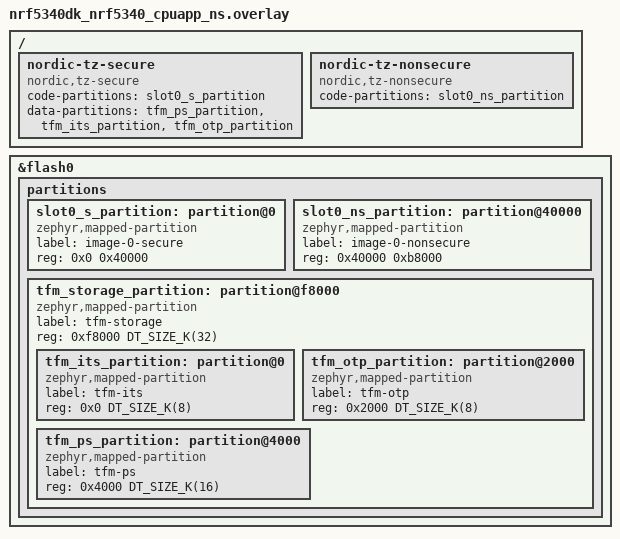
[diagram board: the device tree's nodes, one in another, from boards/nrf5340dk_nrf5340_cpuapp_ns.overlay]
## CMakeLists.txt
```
#
# Copyright (c) 2023 Nordic Semiconductor ASA
#
# SPDX-License-Identifier: LicenseRef-Nordic-5-Clause
#

cmake_minimum_required(VERSION 3.20.0)

if(NOT crypto_service IN_LIST SNIPPET)
  set(SNIPPET crypto_service ${SNIPPET} CACHE STRING "" FORCE)
endif()

find_package(Zephyr REQUIRED HINTS $ENV{ZEPHYR_BASE})

project(pbkdf2)

target_sources(app PRIVATE
        src/main.c)
```

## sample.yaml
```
sample:
  description: |
    This sample demonstrates key derivation using the PBKDF2 algorithm with HMAC-SHA-256.
  name: PBKDF2 sample
common:
  sysbuild: true
  tags:
    - introduction
    - psa
    - sysbuild
    - ci_samples_crypto
    - crypto
  harness: console
  harness_config:
    type: multi_line
    regex:
      - ".*Example finished successfully!.*"
tests:
  sample.pbkdf2.cc3xx:
    tags:
      - cc3xx
    platform_allow:
      - nrf5340dk/nrf5340/cpuapp
      - nrf52840dk/nrf52840
      - nrf5340dk/nrf5340/cpuapp/ns
      - nrf9151dk/nrf9151
      - nrf9151dk/nrf9151/ns
    integration_platforms:
      - nrf5340dk/nrf5340/cpuapp
      - nrf5340dk/nrf5340/cpuapp/ns
      - nrf52840dk/nrf52840
      - nrf9151dk/nrf9151
      - nrf9151dk/nrf9151/ns
  sample.pbkdf2.cracen:
    sysbuild: true
    tags:
      - cracen
    platform_allow:
      - nrf54l15dk/nrf54l15/cpuapp
      - nrf54l15dk/nrf54l15/cpuapp/ns
      - nrf54l15dk/nrf54l10/cpuapp
      - nrf54l15dk/nrf54l10/cpuapp/ns
      - nrf54l15dk/nrf54l05/cpuapp
      - nrf54ls05dk/nrf54ls05a/cpuapp
      - nrf54ls05dk/nrf54ls05b/cpuapp
      - nrf54lm20dk/nrf54lm20a/cpuapp
      - nrf54lm20dk/nrf54lm20a/cpuapp/ns
      - nrf54lm20dk/nrf54lm20b/cpuapp
      - nrf54lm20dk/nrf54lm20b/cpuapp/ns
      - nrf54lv10dk/nrf54lv10a/cpuapp
      - nrf54lv10dk/nrf54lv10a/cpuapp/ns
      - nrf54lc10dk/nrf54lc10a/cpuapp
      - nrf54lc10dk/nrf54lc10a/cpuapp/ns
      - nrf7120dk/nrf7120/cpuapp
      - nrf7120dk/nrf7120/cpuapp/ns
    integration_platforms:
      - nrf54l15dk/nrf54l15/cpuapp
      - nrf54l15dk/nrf54l15/cpuapp/ns
      - nrf54l15dk/nrf54l10/cpuapp
      - nrf54l15dk/nrf54l10/cpuapp/ns
      - nrf54l15dk/nrf54l05/cpuapp
      - nrf54ls05dk/nrf54ls05a/cpuapp
      - nrf54ls05dk/nrf54ls05b/cpuapp
      - nrf54lm20dk/nrf54lm20a/cpuapp
      - nrf54lm20dk/nrf54lm20a/cpuapp/ns
      - nrf54lm20dk/nrf54lm20b/cpuapp
      - nrf54lm20dk/nrf54lm20b/cpuapp/ns
      - nrf54lv10dk/nrf54lv10a/cpuapp
      - nrf54lv10dk/nrf54lv10a/cpuapp/ns
      - nrf54lc10dk/nrf54lc10a/cpuapp
      - nrf54lc10dk/nrf54lc10a/cpuapp/ns
      - nrf7120dk/nrf7120/cpuapp
      - nrf7120dk/nrf7120/cpuapp/ns
  sample.hmac.pbkdf2.crypto_service:
    tags:
      - cracen
    platform_allow:
      - nrf54h20dk/nrf54h20/cpuapp
    integration_platforms:
      - nrf54h20dk/nrf54h20/cpuapp
```

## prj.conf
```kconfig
#
# Copyright (c) 2024 Nordic Semiconductor ASA
#
# SPDX-License-Identifier: LicenseRef-Nordic-5-Clause
#
# The Zephyr CMSIS emulation assumes that ticks are ms, currently
CONFIG_SYS_CLOCK_TICKS_PER_SEC=1000

CONFIG_MAIN_STACK_SIZE=4096
CONFIG_HEAP_MEM_POOL_SIZE=4096

# Enable logging
CONFIG_CONSOLE=y
CONFIG_LOG=y

# Enable cryptographic features
CONFIG_PSA_CRYPTO=y
CONFIG_PSA_WANT_ALG_SHA_256=y
CONFIG_PSA_WANT_ALG_HMAC=y
CONFIG_PSA_WANT_ALG_PBKDF2_HMAC=y
```

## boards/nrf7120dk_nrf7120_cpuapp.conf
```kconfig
#
# Copyright (c) 2025 Nordic Semiconductor ASA
#
# SPDX-License-Identifier: LicenseRef-Nordic-5-Clause
#
# Configure crypto driver
CONFIG_PSA_CRYPTO_DRIVER_OBERON=n
CONFIG_PSA_CRYPTO_DRIVER_CRACEN=y

# Configure MbedTLS
CONFIG_MBEDTLS_ENABLE_HEAP=y
CONFIG_MBEDTLS_HEAP_SIZE=8192
```

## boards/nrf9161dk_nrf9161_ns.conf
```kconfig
CONFIG_TFM_PROFILE_TYPE_NOT_SET=y

# Using hardware crypto accelerator
CONFIG_PSA_CRYPTO_DRIVER_CC3XX=y
```

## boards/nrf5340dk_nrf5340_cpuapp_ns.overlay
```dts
/delete-node/ &boot_partition;
/delete-node/ &slot0_partition;
/delete-node/ &slot1_partition;
/delete-node/ &storage_partition;

/delete-node/ &tfm_its_partition;
/delete-node/ &tfm_otp_partition;
/delete-node/ &tfm_ps_partition;

&flash0 {
	partitions {
		slot0_s_partition: partition@0 {
			compatible = "zephyr,mapped-partition";
			label = "image-0-secure";
			reg = <0x0 0x40000>;
		};

		slot0_ns_partition: partition@40000 {
			compatible = "zephyr,mapped-partition";
			label = "image-0-nonsecure";
			reg = <0x40000 0xb8000>;
		};

		tfm_storage_partition: partition@f8000 {
			compatible = "zephyr,mapped-partition";
			label = "tfm-storage";
			reg = <0xf8000 DT_SIZE_K(32)>;
			ranges = <0x0 0xf8000 DT_SIZE_K(32)>;
			#address-cells = <1>;
			#size-cells = <1>;

			tfm_its_partition: partition@0 {
				compatible = "zephyr,mapped-partition";
				label = "tfm-its";
				reg = <0x0 DT_SIZE_K(8)>;
			};

			tfm_otp_partition: partition@2000 {
				compatible = "zephyr,mapped-partition";
				label = "tfm-otp";
				reg = <0x2000 DT_SIZE_K(8)>;
			};

			tfm_ps_partition: partition@4000 {
				compatible = "zephyr,mapped-partition";
				label = "tfm-ps";
				reg = <0x4000 DT_SIZE_K(16)>;
			};
		};
	};
};

/ {
	/delete-node/ nordic-tz-secure;
	/delete-node/ nordic-tz-nonsecure;

	nordic-tz-secure {
		compatible = "nordic,tz-secure";
		code-partitions = <&slot0_s_partition>;
		data-partitions = <&tfm_ps_partition>,
				  <&tfm_its_partition>,
				  <&tfm_otp_partition>;
	};

	nordic-tz-nonsecure {
		compatible = "nordic,tz-nonsecure";
		code-partitions = <&slot0_ns_partition>;
	};
};
```

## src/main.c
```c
/*
 * Copyright (c) 2023 Nordic Semiconductor ASA
 *
 * SPDX-License-Identifier: LicenseRef-Nordic-5-Clause
 */

#include <zephyr/kernel.h>
#include <zephyr/logging/log.h>
#include <stdint.h>
#include <psa/crypto.h>

#ifdef CONFIG_BUILD_WITH_TFM
#include <tfm_ns_interface.h>
#endif

#define APP_SUCCESS		(0)
#define APP_ERROR		(-1)
#define APP_SUCCESS_MESSAGE "Example finished successfully!"
#define APP_ERROR_MESSAGE "Example exited with error!"

#define PRINT_HEX(p_label, p_text, len)\
	({\
		LOG_INF("---- %s (len: %u): ----", p_label, len);\
		LOG_HEXDUMP_INF(p_text, len, "Content:");\
		LOG_INF("---- %s end  ----", p_label);\
	})

LOG_MODULE_REGISTER(pkbdf2, LOG_LEVEL_DBG);

/* ====================================================================== */
/*        Global variables/defines for the PBKDF2 example                 */

#define PBKDF2_SAMPLE_INPUT_KEY_SIZE (6)
#define PBKDF2_SAMPLE_SALT_SIZE (4)
#define PBKDF2_SAMPLE_OUTPUT_KEY_SIZE (64)

/* Test data from RFC 5869 Test Case 2
 * https://datatracker.ietf.org/doc/html/rfc7914.html#section-11
 */
static const uint8_t m_input_password[PBKDF2_SAMPLE_INPUT_KEY_SIZE] = {
	'p', 'a', 's', 's', 'w', 'd',
};

static const uint8_t m_salt[PBKDF2_SAMPLE_SALT_SIZE] = {
	's', 'a', 'l', 't'
};

/* (NIST) "Recommendation for Password-Based Key Derivation:
 * The iteration count shall be  selected as large as possible, as
 * long as the time required to generate the key using the entered
 * password is acceptable for the users. [...] A minimum iteration
 * count of 1,000 is recommended.
 */
static uint32_t m_iteration_count = 1;

/* Buffer to hold the output generated from PKBD2S */
static uint8_t m_output_key[PBKDF2_SAMPLE_OUTPUT_KEY_SIZE];

static const uint8_t m_expected_output_key[PBKDF2_SAMPLE_OUTPUT_KEY_SIZE] = {
	0x55, 0xac, 0x04, 0x6e, 0x56, 0xe3, 0x08, 0x9f,
	0xec, 0x16, 0x91, 0xc2, 0x25, 0x44, 0xb6, 0x05,
	0xf9, 0x41, 0x85, 0x21, 0x6d, 0xde, 0x04, 0x65,
	0xe6, 0x8b, 0x9d, 0x57, 0xc2, 0x0d, 0xac, 0xbc,
	0x49, 0xca, 0x9c, 0xcc, 0xf1, 0x79, 0xb6, 0x45,
	0x99, 0x16, 0x64, 0xb3, 0x9d, 0x77, 0xef, 0x31,
	0x7c, 0x71, 0xb8, 0x45, 0xb1, 0xe3, 0x0b, 0xd5,
	0x09, 0x11, 0x20, 0x41, 0xd3, 0xa1, 0x97, 0x83,
};

static psa_key_id_t m_input_key_id;
static psa_key_id_t m_output_key_id;
/* ====================================================================== */

int crypto_init(void)
{
	psa_status_t status;

	/* Initialize PSA Crypto */
	status = psa_crypto_init();
	if (status != PSA_SUCCESS) {
		return APP_ERROR;
	}

	return APP_SUCCESS;
}

int crypto_finish(void)
{
	psa_status_t status;

	/* Destroy the key handle */
	status = psa_destroy_key(m_input_key_id);
	if (status != PSA_SUCCESS) {
		LOG_INF("psa_destroy_key failed! (Error: %d)", status);
		return APP_ERROR;
	}

	status = psa_destroy_key(m_output_key_id);
	if (status != PSA_SUCCESS) {
		LOG_INF("psa_destroy_key failed! (Error: %d)", status);
		return APP_ERROR;
	}

	return APP_SUCCESS;
}

int import_input_password(void)
{
	psa_status_t status;
	psa_key_attributes_t attributes = PSA_KEY_ATTRIBUTES_INIT;

	psa_set_key_usage_flags(&attributes, PSA_KEY_USAGE_DERIVE);
	psa_set_key_lifetime(&attributes, PSA_KEY_LIFETIME_VOLATILE);
	psa_set_key_algorithm(&attributes, PSA_ALG_PBKDF2_HMAC(PSA_ALG_SHA_256));
	psa_set_key_type(&attributes, PSA_KEY_TYPE_PASSWORD);
	psa_set_key_bits(&attributes, PSA_BYTES_TO_BITS(PBKDF2_SAMPLE_INPUT_KEY_SIZE));

	status = psa_import_key(&attributes, m_input_password, PBKDF2_SAMPLE_INPUT_KEY_SIZE,
				&m_input_key_id);
	if (status != PSA_SUCCESS) {
		LOG_INF("psa_import_key failed! (Error: %d)", status);
		return APP_ERROR;
	}

	return APP_SUCCESS;
}

int derive_output_key(void)
{
	psa_status_t status;
	int cmp_status;
	psa_key_derivation_operation_t operation = PSA_KEY_DERIVATION_OPERATION_INIT;

	status = psa_key_derivation_setup(&operation, PSA_ALG_PBKDF2_HMAC(PSA_ALG_SHA_256));
	if (status != PSA_SUCCESS) {
		LOG_INF("psa_key_derivation_setup failed! (Error: %d)", status);
		return APP_ERROR;
	}

	status = psa_key_derivation_input_integer(&operation, PSA_KEY_DERIVATION_INPUT_COST,
						  m_iteration_count);
	if (status != PSA_SUCCESS) {
		LOG_INF("psa_key_derivation_input_integer failed! (Error: %d)", status);
		return APP_ERROR;
	}

	status = psa_key_derivation_input_bytes(&operation, PSA_KEY_DERIVATION_INPUT_SALT, m_salt,
						PBKDF2_SAMPLE_SALT_SIZE);
	if (status != PSA_SUCCESS) {
		LOG_INF("psa_key_derivation_input_bytes failed! (Error: %d)", status);
		return APP_ERROR;
	}

	status = psa_key_derivation_input_key(&operation, PSA_KEY_DERIVATION_INPUT_PASSWORD,
					      m_input_key_id);
	if (status != PSA_SUCCESS) {
		LOG_INF("psa_key_derivation_input_key failed! (Error: %d)", status);
		return APP_ERROR;
	}

	/* This outputs the derived key as bytes to the application.
	 * If the derived key is to be used for in cryptographic operations use
	 * psa_key_derivation_output_key instead.
	 */
	status = psa_key_derivation_output_bytes(&operation, m_output_key,
						 PBKDF2_SAMPLE_OUTPUT_KEY_SIZE);
	if (status != PSA_SUCCESS) {
		LOG_INF("psa_key_derivation_output_bytes failed! (Error: %d)", status);
		return APP_ERROR;
	}

	status = psa_key_derivation_abort(&operation);
	if (status != PSA_SUCCESS) {
		LOG_INF("psa_key_derivation_abort failed! (Error: %d)", status);
		return APP_ERROR;
	}

	LOG_INF("Compare derived key with expected value...");
	cmp_status = memcmp(m_expected_output_key, m_output_key, sizeof(m_output_key));
	if (cmp_status != 0) {
		LOG_INF("Error, the derived key doesn't match the expected value!");
		return APP_ERROR;
	}

	LOG_INF("Key derivation successful!");
	PRINT_HEX("Password", m_input_password, sizeof(m_input_password));
	PRINT_HEX("Salt", m_salt, sizeof(m_salt));
	LOG_INF("Iteration count: %d", m_iteration_count);
	PRINT_HEX("Derived key", m_output_key, sizeof(m_output_key));

	return APP_SUCCESS;
}


int main(void)
{
	int status;

	LOG_INF("Starting PBKDF2 example...");

	status = crypto_init();
	if (status != APP_SUCCESS) {
		LOG_INF(APP_ERROR_MESSAGE);
		return APP_ERROR;
	}

	status = import_input_password();
	if (status != APP_SUCCESS) {
		LOG_INF(APP_ERROR_MESSAGE);
		return APP_ERROR;
	}

	status = derive_output_key();
	if (status != APP_SUCCESS) {
		LOG_INF(APP_ERROR_MESSAGE);
		return APP_ERROR;
	}

	status = crypto_finish();
	if (status != APP_SUCCESS) {
		LOG_INF(APP_ERROR_MESSAGE);
		return APP_ERROR;
	}

	LOG_INF(APP_SUCCESS_MESSAGE);

	return APP_SUCCESS;
}
```
